# HDSC_HC32L110 register map
Vendor: HDSC Co.Ltd; Series: ARMCM0P; File version: 1.2
CPU: CM0 r0p0, little endian, no MPU, no FPU, 3 interrupt priority bits
Registers are 32-bit, read-write, reset 0x0 unless marked. A register's access mark holds for its fields unless they carry their own. Offsets are from the block's base; [hi:lo] are bit positions; {n}, {i} and the like mark numbered series; 'fields as' and 'values as' point back to an identical list.

## LPTIMER
Base 0x40000C00; alternate view of BT0
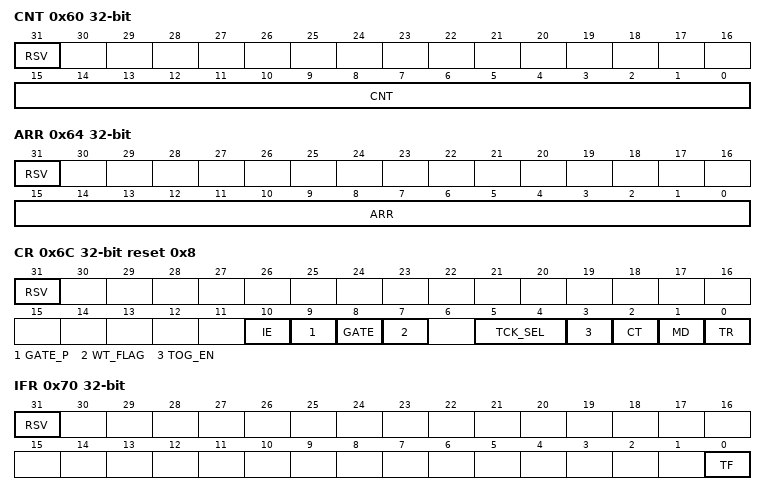
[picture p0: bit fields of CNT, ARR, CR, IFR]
0x60 CNT ro (reset mask 0xFFFF)
  [31] RSV rw, [15:0] CNT
0x64 ARR (reset mask 0xFFFF)
  [31] RSV, [15:0] ARR
0x6C CR reset 0x8 (reset mask 0x7BF)
  [31] RSV, [10] IE, [9] GATE_P, [8] GATE, [7] WT_FLAG ro, [5:4] TCK_SEL, [3] TOG_EN, [2] CT, [1] MD, [0] TR
0x70 IFR ro (reset mask 0x1)
  [31] RSV rw, [0] TF
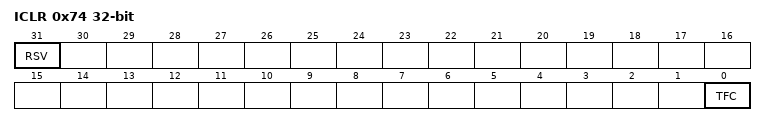
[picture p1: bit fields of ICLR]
0x74 ICLR wo (reset mask 0x1)
  [31] RSV rw, [0] TFC

## LPUART
Base 0x40000200
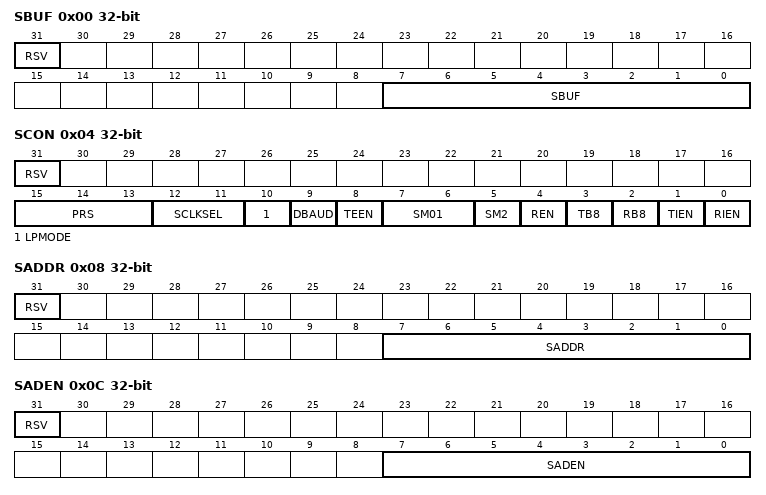
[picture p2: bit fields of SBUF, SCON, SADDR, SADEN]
0x00 SBUF (reset mask 0xFF)
  [31] RSV, [7:0] SBUF
0x04 SCON (reset mask 0xFFFF)
  [31] RSV, [15:13] PRS, [12:11] SCLKSEL, [10] LPMODE, [9] DBAUD, [8] TEEN, [7:6] SM01, [5] SM2, [4] REN, [3] TB8, [2] RB8, [1] TIEN, [0] RIEN
0x08 SADDR (reset mask 0xFF)
  [31] RSV, [7:0] SADDR
0x0C SADEN (reset mask 0xFF)
  [31] RSV, [7:0] SADEN
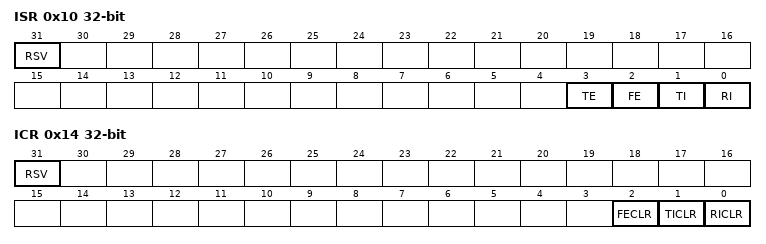
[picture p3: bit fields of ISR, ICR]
0x10 ISR ro (reset mask 0xF)
  [31] RSV rw, [3] TE, [2] FE, [1] TI, [0] RI
0x14 ICR wo (reset mask 0x7)
  [31] RSV rw, [2] FECLR, [1] TICLR, [0] RICLR

## LVD
Base 0x40002400; alternate view of ADC
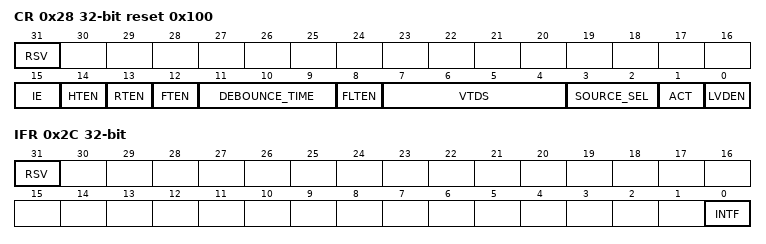
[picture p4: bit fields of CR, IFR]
0x28 CR reset 0x100 (reset mask 0xFFFF)
  [31] RSV, [15] IE, [14] HTEN, [13] RTEN, [12] FTEN, [11:9] DEBOUNCE_TIME, [8] FLTEN, [7:4] VTDS, [3:2] SOURCE_SEL, [1] ACT, [0] LVDEN
0x2C IFR (reset mask 0x1)
  [31] RSV, [0] INTF

## PCA
Base 0x40001000
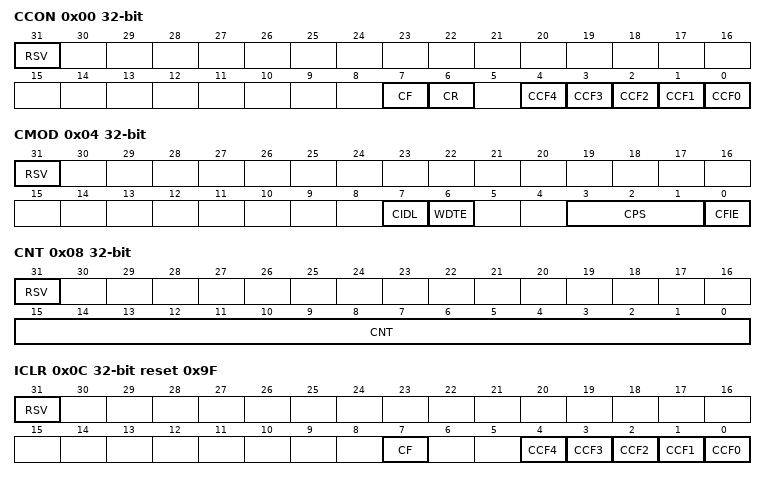
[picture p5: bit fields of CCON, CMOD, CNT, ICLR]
0x00 CCON (reset mask 0xDF)
  [31] RSV, [7] CF, [6] CR, [n] CCF{n} (n=0..4)
0x04 CMOD (reset mask 0xDF)
  [31] RSV, [7] CIDL, [6] WDTE, [3:1] CPS, [0] CFIE
0x08 CNT (reset mask 0xFFFF)
  [31] RSV, [15:0] CNT
0x0C ICLR wo reset 0x9F (reset mask 0x9F)
  [31] RSV rw, [7] CF, [n] CCF{n} (n=0..4)
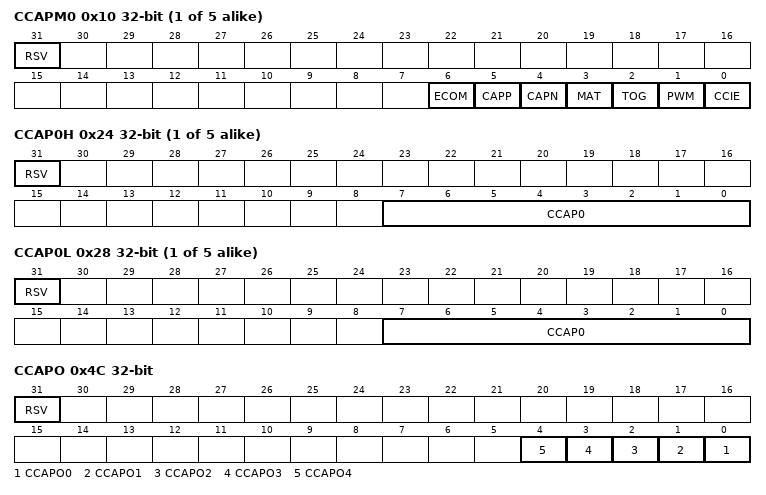
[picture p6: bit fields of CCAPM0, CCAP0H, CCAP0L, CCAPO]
{0x10+4i} CCAPM{i} (reset mask 0x7F) (i=0..4)
  [31] RSV, [6] ECOM, [5] CAPP, [4] CAPN, [3] MAT, [2] TOG, [1] PWM, [0] CCIE
{0x24+8i} CCAP{i}H (reset mask 0xFF) (i=0..4)
  [31] RSV, [7:0] CCAP{i}
{0x28+8i} CCAP{i}L (reset mask 0xFF) (i=0..4)
  [31] RSV, [7:0] CCAP{i}
0x4C CCAPO (reset mask 0x1F)
  [31] RSV, [n] CCAPO{n} (n=0..4)
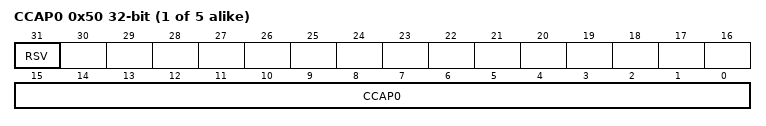
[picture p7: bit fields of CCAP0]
{0x50+4i} CCAP{i} (reset mask 0xFFFF) (i=0..4)
  [31] RSV, [15:0] CCAP{i}

## RAM
Base 0x40020400
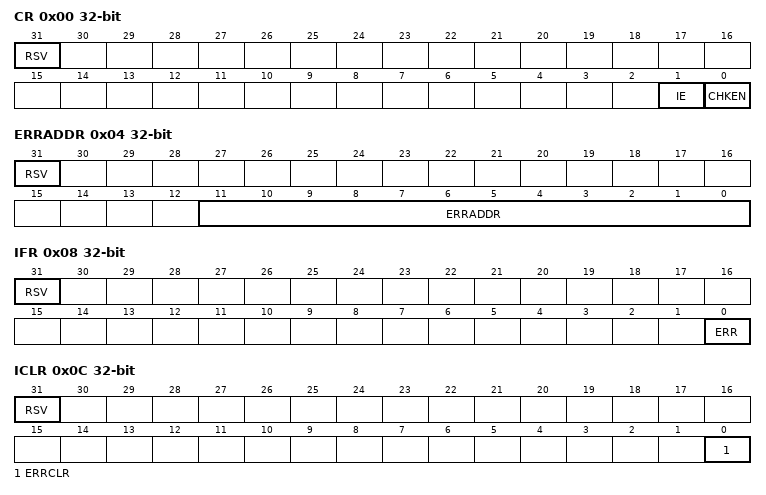
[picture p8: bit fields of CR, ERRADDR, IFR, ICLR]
0x00 CR (reset mask 0x3)
  [31] RSV, [1] IE, [0] CHKEN
0x04 ERRADDR ro (reset mask 0xFFF)
  [31] RSV rw, [11:0] ERRADDR
0x08 IFR ro (reset mask 0x1)
  [31] RSV rw, [0] ERR
0x0C ICLR ro (reset mask 0x1)
  [31] RSV rw, [0] ERRCLR wo

## RESET
Base 0x4000201C
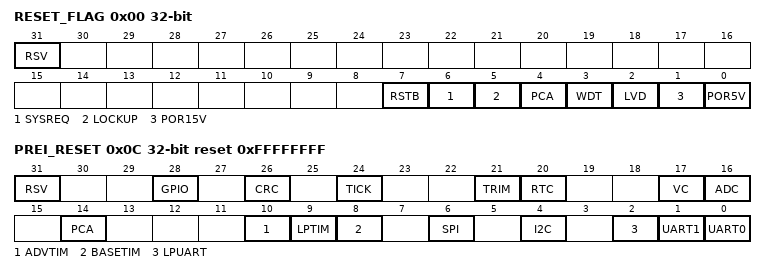
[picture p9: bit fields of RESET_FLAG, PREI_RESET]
0x00 RESET_FLAG
  [31] RSV, [7] RSTB, [6] SYSREQ, [5] LOCKUP, [4] PCA, [3] WDT, [2] LVD, [1] POR15V, [0] POR5V
0x0C PREI_RESET reset 0xFFFFFFFF
  [31] RSV, [28] GPIO, [26] CRC, [24] TICK, [21] TRIM, [20] RTC, [17] VC, [16] ADC, [14] PCA, [10] ADVTIM, [9] LPTIM, [8] BASETIM, [6] SPI, [4] I2C, [2] LPUART, [1] UART1, [0] UART0

## RTC
Base 0x40001400
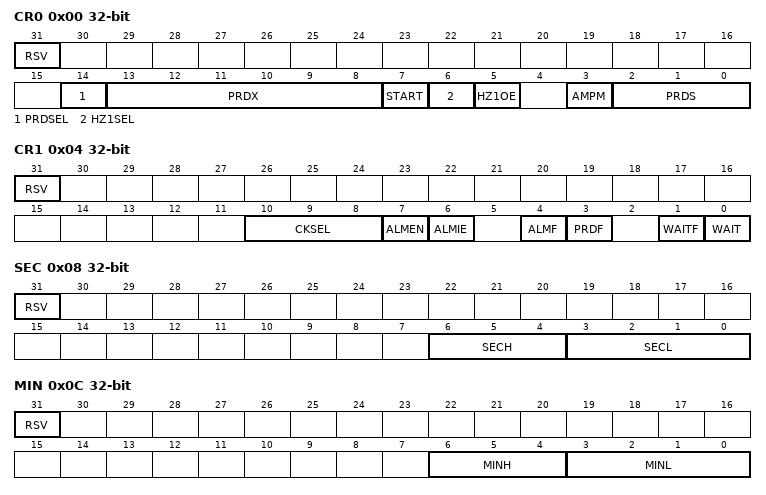
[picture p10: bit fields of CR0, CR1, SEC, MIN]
0x00 CR0 (reset mask 0x7FEF)
  [31] RSV, [14] PRDSEL, [13:8] PRDX, [7] START, [6] HZ1SEL, [5] HZ1OE, [3] AMPM, [2:0] PRDS
0x04 CR1 (reset mask 0x7FB)
  [31] RSV, [10:8] CKSEL, [7] ALMEN, [6] ALMIE, [4] ALMF, [3] PRDF, [1] WAITF, [0] WAIT
0x08 SEC (reset mask 0x7F)
  [31] RSV, [6:4] SECH, [3:0] SECL
0x0C MIN (reset mask 0x7F)
  [31] RSV, [6:4] MINH, [3:0] MINL
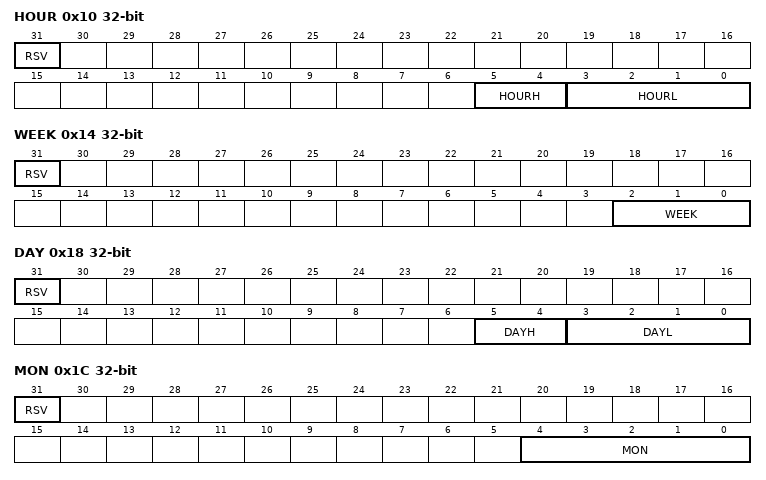
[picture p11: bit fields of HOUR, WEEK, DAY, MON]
0x10 HOUR (reset mask 0x7F)
  [31] RSV, [5:4] HOURH, [3:0] HOURL
0x14 WEEK (reset mask 0x7)
  [31] RSV, [2:0] WEEK
0x18 DAY (reset mask 0x3F)
  [31] RSV, [5:4] DAYH, [3:0] DAYL
0x1C MON (reset mask 0x1F)
  [31] RSV, [4:0] MON
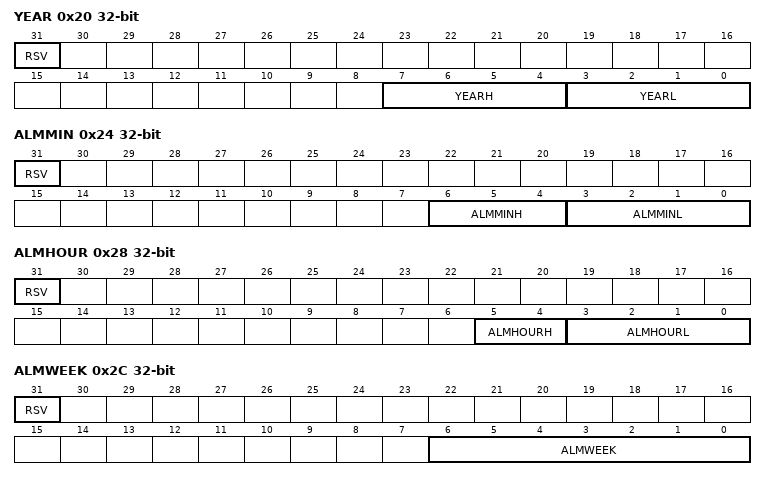
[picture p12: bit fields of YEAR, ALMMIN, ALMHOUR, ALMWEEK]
0x20 YEAR (reset mask 0xFF)
  [31] RSV, [7:4] YEARH, [3:0] YEARL
0x24 ALMMIN (reset mask 0x7F)
  [31] RSV, [6:4] ALMMINH, [3:0] ALMMINL
0x28 ALMHOUR (reset mask 0x3F)
  [31] RSV, [5:4] ALMHOURH, [3:0] ALMHOURL
0x2C ALMWEEK (reset mask 0x7F)
  [31] RSV, [6:0] ALMWEEK
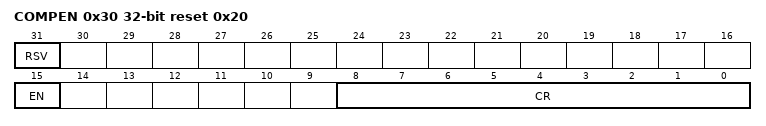
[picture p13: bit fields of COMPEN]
0x30 COMPEN reset 0x20 (reset mask 0x81FF)
  [31] RSV, [15] EN, [8:0] CR

## SPI
Base 0x40000800
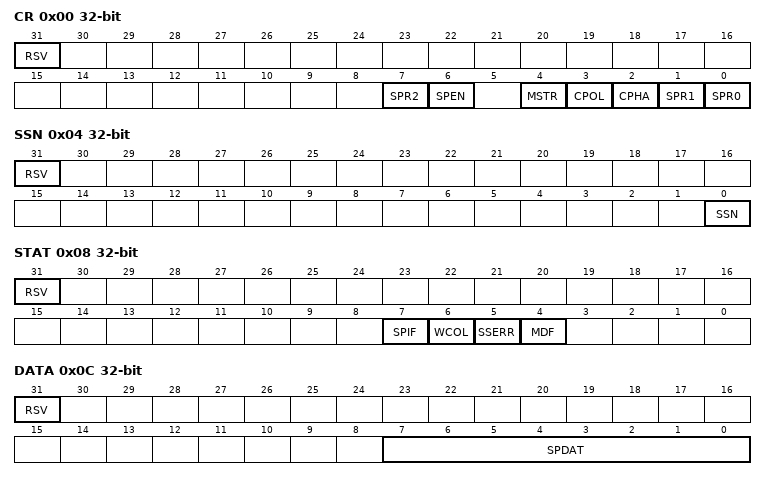
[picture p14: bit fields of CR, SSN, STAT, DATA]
0x00 CR (reset mask 0xDF)
  [31] RSV, [7] SPR2, [6] SPEN, [4] MSTR, [3] CPOL, [2] CPHA, [1] SPR1, [0] SPR0
0x04 SSN (reset mask 0x1)
  [31] RSV, [0] SSN
0x08 STAT ro (reset mask 0xF0)
  [31] RSV rw, [7] SPIF, [6] WCOL, [5] SSERR, [4] MDF
0x0C DATA (reset mask 0xFF)
  [31] RSV, [7:0] SPDAT

## UART0 — desc UART
Base 0x40000000
Same registers: UART1 0x40000100
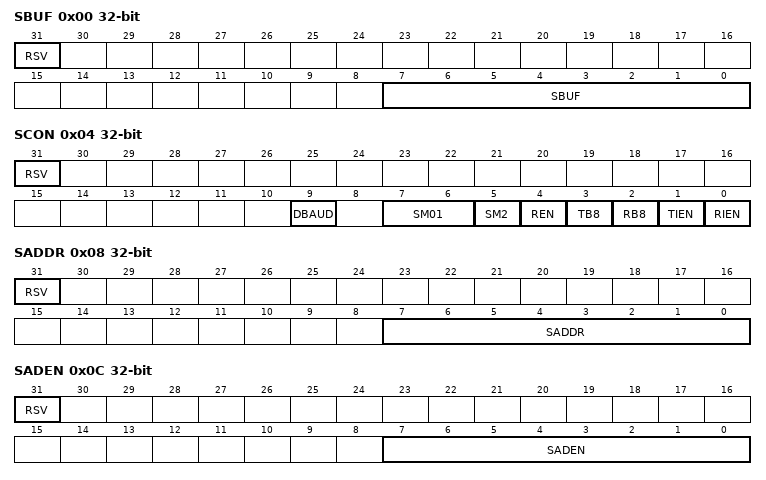
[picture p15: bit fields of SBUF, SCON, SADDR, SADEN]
0x00 SBUF (reset mask 0xFF)
  [31] RSV, [7:0] SBUF
0x04 SCON (reset mask 0x2FF)
  [31] RSV, [9] DBAUD, [7:6] SM01, [5] SM2, [4] REN, [3] TB8, [2] RB8, [1] TIEN, [0] RIEN
0x08 SADDR (reset mask 0xFF)
  [31] RSV, [7:0] SADDR
0x0C SADEN (reset mask 0xFF)
  [31] RSV, [7:0] SADEN
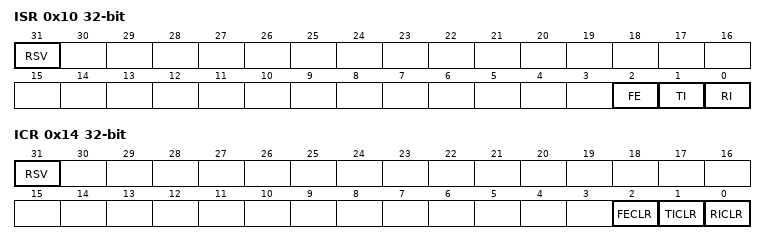
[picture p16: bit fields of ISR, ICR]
0x10 ISR ro (reset mask 0xF)
  [31] RSV rw, [2] FE, [1] TI, [0] RI
0x14 ICR wo (reset mask 0x7)
  [31] RSV rw, [2] FECLR, [1] TICLR rw, [0] RICLR rw

## VC
Base 0x40002400; alternate view of ADC
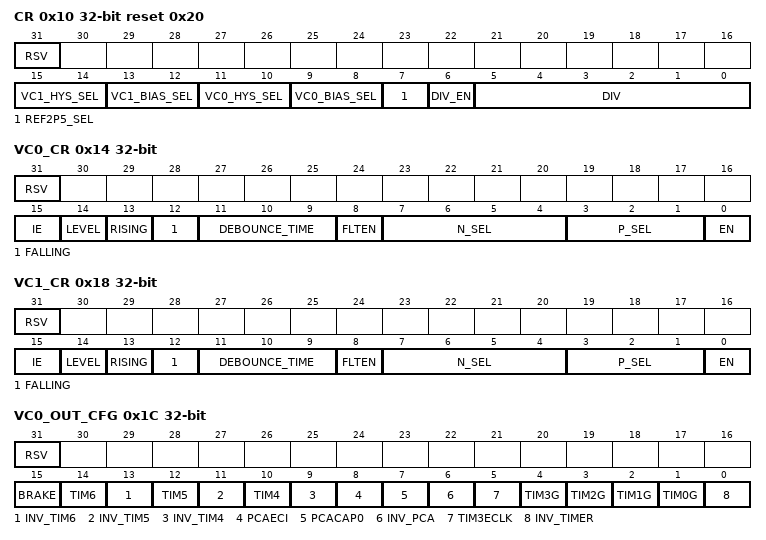
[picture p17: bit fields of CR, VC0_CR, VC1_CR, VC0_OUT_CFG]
0x10 CR reset 0x20 (reset mask 0xFFFF)
  [31] RSV, [15:14] VC1_HYS_SEL, [13:12] VC1_BIAS_SEL, [11:10] VC0_HYS_SEL, [9:8] VC0_BIAS_SEL, [7] REF2P5_SEL, [6] DIV_EN, [5:0] DIV
0x14 VC0_CR (reset mask 0xFFFF)
  [31] RSV, [15] IE, [14] LEVEL, [13] RISING, [12] FALLING, [11:9] DEBOUNCE_TIME, [8] FLTEN, [7:4] N_SEL, [3:1] P_SEL, [0] EN
0x18 VC1_CR (reset mask 0xFFFF)
  fields as VC0_CR
0x1C VC0_OUT_CFG (reset mask 0xFFFF)
  [31] RSV, [15] BRAKE, [14] TIM6, [13] INV_TIM6, [12] TIM5, [11] INV_TIM5, [10] TIM4, [9] INV_TIM4, [8] PCAECI, [7] PCACAP0, [6] INV_PCA, [5] TIM3ECLK, [n+1] TIM{n}G (n=0..3), [0] INV_TIMER
0x20 VC1_OUT_CFG (reset mask 0xFFFF)
  fields as VC0_OUT_CFG
0x24 IFR (reset mask 0xF)
  [31] RSV, [3] VC1_FILTER ro, [2] VC0_FILTER ro, [1] VC1_INTF, [0] VC0_INTF

## WDT
Base 0x40000C00; alternate view of BT0
0x80 RST wo (reset mask 0xFF)
  [31] RSV rw, [7:0] WDTRST
0x84 CON reset 0xF (reset mask 0xFFBF)
  [31] RSV, [15:8] WCNTL ro, [7] WDINT ro, [5] WINT_EN, [4] WDTR ro, [3:0] WOV
